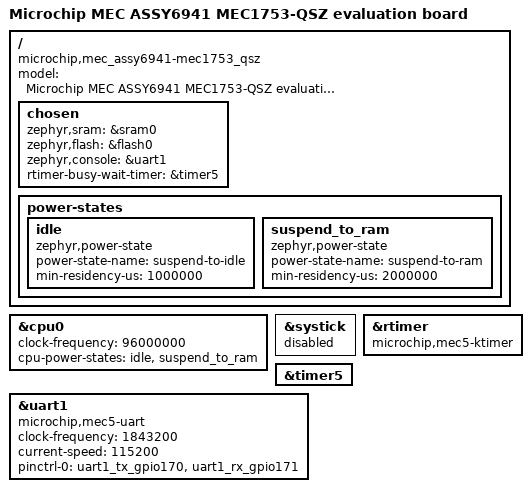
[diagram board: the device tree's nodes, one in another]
/*
 * Copyright (c) 2025, Microchip Technology Inc.
 *
 * SPDX-License-Identifier: Apache-2.0
 */

/dts-v1/;

#include <microchip/mec5_mec1753qsz.dtsi>
#include <microchip/mec5/mec1753qsz-a0-pinctrl.dtsi>

/ {
	model = "Microchip MEC ASSY6941 MEC1753-QSZ evaluation board";
	compatible = "microchip,mec_assy6941-mec1753_qsz";

	chosen {
		zephyr,sram = &sram0;
		zephyr,flash = &flash0;
		zephyr,console = &uart1;
		rtimer-busy-wait-timer = &timer5;
	};

	power-states {
		idle: idle {
			compatible = "zephyr,power-state";
			power-state-name = "suspend-to-idle";
			min-residency-us = <1000000>;
		};

		suspend_to_ram: suspend_to_ram {
			compatible = "zephyr,power-state";
			power-state-name = "suspend-to-ram";
			min-residency-us = <2000000>;
		};
	};
};

&cpu0 {
	clock-frequency = <96000000>;
	status = "okay";
	cpu-power-states = <&idle &suspend_to_ram>;
};

/* Disable ARM SysTick kernel timer driver */
&systick {
	status = "disabled";
};

/* Enable MCHP kernel timer driver using 32KHz RTOS timer and 1MHz basic timer */
&rtimer {
	compatible = "microchip,mec5-ktimer";
	status = "okay";
};

/* We chose 32-bit basic timer 5 for use by ktimer */
&timer5 {
	status = "okay";
};

&uart1 {
	compatible = "microchip,mec5-uart";
	status = "okay";
	clock-frequency = <1843200>;
	current-speed = <115200>;
	pinctrl-0 = <&uart1_tx_gpio170 &uart1_rx_gpio171>;
	pinctrl-names = "default";
};
